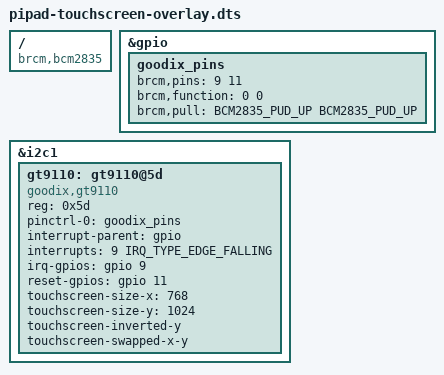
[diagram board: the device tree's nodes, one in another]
/dts-v1/;
/plugin/;

#include <dt-bindings/interrupt-controller/irq.h>
#include <dt-bindings/gpio/gpio.h>
#include <dt-bindings/pinctrl/bcm2835.h>
#include <dt-bindings/clock/bcm2835.h>


/*

tried:
- changing interrupts to IRQ_TYPE_LEVEL_HIGH

Things to try:
- changing pull-up on interrupt pin to None


*/

/ {
    compatible = "brcm,bcm2835";

    fragment@0 {
        target = <&gpio>;
        __overlay__ {
            goodix_pins: goodix_pins {
                brcm,pins = <9 11>; // interrupt and reset
                brcm,function = <0 0>; // in
                brcm,pull = <BCM2835_PUD_UP BCM2835_PUD_UP>; // pull-up
            };
        };
    };

    fragment@1 {
        target = <&i2c1>;
        __overlay__ {
            #address-cells = <1>;
            #size-cells = <0>;
            status = "okay";

            gt9110: gt9110@5d {
                compatible = "goodix,gt9110";
                reg = <0x5d>;
                pinctrl-names = "default";
                pinctrl-0 = <&goodix_pins>;
                interrupt-parent = <&gpio>;
                interrupts = <9 IRQ_TYPE_EDGE_FALLING>;
                irq-gpios = <&gpio 9 GPIO_ACTIVE_HIGH>;
                reset-gpios = <&gpio 11 GPIO_ACTIVE_HIGH>;
                touchscreen-size-x = <768>;
                touchscreen-size-y = <1024>;

                touchscreen-inverted-y;
                touchscreen-swapped-x-y;
            };
        };
    };

    __overrides__ {
        interrupt = <&goodix_pins>,"brcm,pins:0",
            <&gt9110>,"interrupts:0",
            <&gt9110>,"irq-gpios:9";
        reset = <&goodix_pins>,"brcm,pins:11",
            <&gt9110>,"reset-gpios:11";
    };
};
